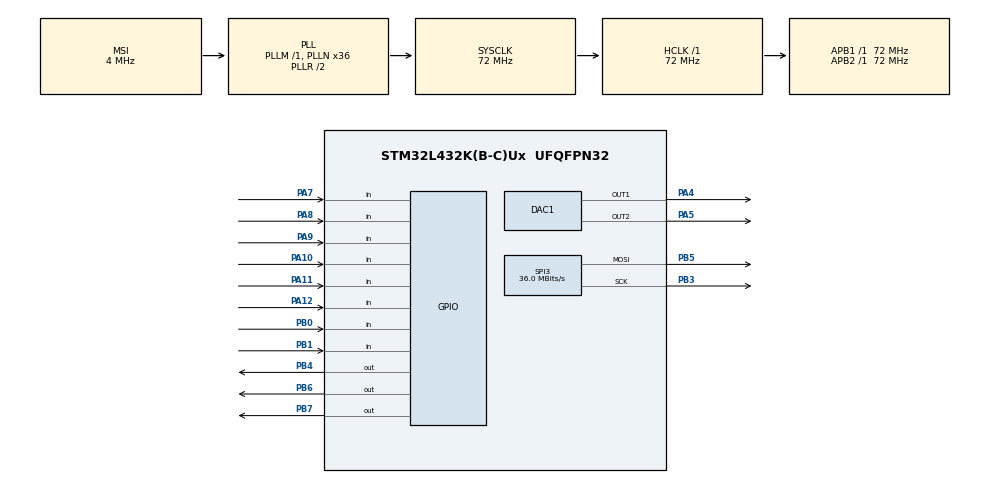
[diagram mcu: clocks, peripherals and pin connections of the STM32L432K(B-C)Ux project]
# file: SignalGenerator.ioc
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DAC1.DAC_Channel-DAC_OUT2=DAC_CHANNEL_2
DAC1.DAC_Trigger-DAC_OUT1=DAC_TRIGGER_T2_TRGO
DAC1.DAC_Trigger-DAC_OUT2=DAC_TRIGGER_T6_TRGO
Dma.DAC_CH1.0.Direction=DMA_MEMORY_TO_PERIPH
Dma.DAC_CH1.0.Instance=DMA1_Channel3
Dma.DAC_CH1.0.MemDataAlignment=DMA_MDATAALIGN_WORD
Dma.DAC_CH1.0.MemInc=DMA_MINC_ENABLE
Dma.DAC_CH1.0.Mode=DMA_CIRCULAR
Dma.DAC_CH1.0.PeriphDataAlignment=DMA_PDATAALIGN_WORD
Dma.DAC_CH1.0.PeriphInc=DMA_PINC_DISABLE
Dma.DAC_CH1.0.Priority=DMA_PRIORITY_HIGH
Dma.DAC_CH2.1.Direction=DMA_MEMORY_TO_PERIPH
Dma.DAC_CH2.1.Instance=DMA1_Channel4
Dma.DAC_CH2.1.MemDataAlignment=DMA_MDATAALIGN_WORD
Dma.DAC_CH2.1.MemInc=DMA_MINC_ENABLE
Dma.DAC_CH2.1.Mode=DMA_CIRCULAR
Dma.DAC_CH2.1.PeriphDataAlignment=DMA_PDATAALIGN_WORD
Dma.DAC_CH2.1.PeriphInc=DMA_PINC_DISABLE
Dma.DAC_CH2.1.Priority=DMA_PRIORITY_HIGH
Dma.Request0=DAC_CH1
Dma.Request1=DAC_CH2
Mcu.Family=STM32L4
Mcu.Name=STM32L432K(B-C)Ux
Mcu.Package=UFQFPN32
NVIC.DMA1_Channel3_IRQn=true\:0\:0\:false\:false\:true\:false\:true\:true
NVIC.DMA1_Channel4_IRQn=true\:0\:0\:false\:false\:true\:false\:true\:true
NVIC.PriorityGroup=NVIC_PRIORITYGROUP_4
NVIC.TIM1_UP_TIM16_IRQn=true\:0\:0\:false\:false\:true\:true\:true\:true
NVIC.TIM7_IRQn=true\:0\:0\:false\:false\:true\:true\:true\:true
PA0.GPIO_Label=MCO [High speed clock in]
PA0.Mode=HSE-External-Clock-Source-for-LittleOrca
PA0.Signal=RCC_CK_IN
PA10.GPIO_PuPd=GPIO_PULLUP
PA10.Signal=GPIO_Input
PA11.GPIO_PuPd=GPIO_PULLUP
PA11.Signal=GPIO_Input
PA12.GPIO_PuPd=GPIO_PULLUP
PA12.Signal=GPIO_Input
PA13\ (JTMS-SWDIO).GPIO_Label=SWDIO
PA13\ (JTMS-SWDIO).Mode=Serial_Wire
PA13\ (JTMS-SWDIO).Signal=SYS_JTMS-SWDIO
PA14\ (JTCK-SWCLK).GPIO_Label=SWCLK
PA14\ (JTCK-SWCLK).Mode=Serial_Wire
PA14\ (JTCK-SWCLK).Signal=SYS_JTCK-SWCLK
PA15\ (JTDI).GPIO_Label=VCP_RX
PA15\ (JTDI).Signal=USART2_RX
PA2.GPIO_Label=VCP_TX
PA2.Signal=USART2_TX
PA4.Signal=COMP_DAC11_group
PA5.Signal=COMP_DAC12_group
PA7.GPIO_PuPd=GPIO_PULLUP
PA7.Signal=GPIO_Input
PA8.GPIO_PuPd=GPIO_PULLUP
PA8.Signal=GPIO_Input
PA9.GPIO_PuPd=GPIO_PULLUP
PA9.Signal=GPIO_Input
PB0.GPIO_PuPd=GPIO_PULLUP
PB0.Signal=GPIO_Input
PB1.GPIO_PuPd=GPIO_PULLUP
PB1.Signal=GPIO_Input
PB3\ (JTDO-TRACESWO).Mode=TX_Only_Simplex_Unidirect_Master
PB3\ (JTDO-TRACESWO).Signal=SPI3_SCK
PB4\ (NJTRST).Signal=GPIO_Output
PB5.Mode=TX_Only_Simplex_Unidirect_Master
PB5.Signal=SPI3_MOSI
PB6.Signal=GPIO_Output
PB7.Signal=GPIO_Output
PC14-OSC32_IN\ (PC14).Mode=LSE-External-Oscillator
PC14-OSC32_IN\ (PC14).Signal=RCC_OSC32_IN
PC15-OSC32_OUT\ (PC15).Mode=LSE-External-Oscillator
PC15-OSC32_OUT\ (PC15).Signal=RCC_OSC32_OUT
ProjectManager.HeapSize=0x200
ProjectManager.StackSize=0x400
ProjectManager.TargetToolchain=STM32CubeIDE
RCC.AHBFreq_Value=72000000
RCC.APB1Freq_Value=72000000
RCC.APB1TimFreq_Value=72000000
RCC.APB2Freq_Value=72000000
RCC.APB2TimFreq_Value=72000000
RCC.CortexFreq_Value=72000000
RCC.HCLKFreq_Value=72000000
RCC.HSE_VALUE=8000000
RCC.HSI16_VALUE=16000000
RCC.HSI48_VALUE=48000000
RCC.HSI_VALUE=16000000
RCC.MSI_VALUE=4000000
RCC.PLLMUL=RCC_PLLMUL_4
RCC.PLLN=36
RCC.SYSCLKFreq_VALUE=72000000
RCC.SYSCLKSource=RCC_SYSCLKSOURCE_PLLCLK
RCC.VCOOutputFreq_Value=144000000
SH.COMP_DAC11_group.0=DAC1_OUT1,DAC_OUT1
SH.COMP_DAC12_group.0=DAC1_OUT2,DAC_OUT2
SPI3.BaudRatePrescaler=SPI_BAUDRATEPRESCALER_2
SPI3.CalculateBaudRate=36.0 MBits/s
SPI3.DataSize=SPI_DATASIZE_8BIT
SPI3.Direction=SPI_DIRECTION_2LINES
SPI3.Mode=SPI_MODE_MASTER
SPI3.VirtualType=VM_MASTER
TIM16.Period=61000
TIM16.Prescaler=1200
TIM2.AutoReloadPreload=TIM_AUTORELOAD_PRELOAD_DISABLE
TIM2.Period=624
TIM2.Prescaler=4
TIM2.TIM_MasterOutputTrigger=TIM_TRGO_UPDATE
TIM6.AutoReloadPreload=TIM_AUTORELOAD_PRELOAD_DISABLE
TIM6.Period=624
TIM6.Prescaler=4
TIM6.TIM_MasterOutputTrigger=TIM_TRGO_UPDATE
TIM7.Period=5000
TIM7.Prescaler=28
VP_TIM16_VS_ClockSourceINT.Mode=Enable_Timer
VP_TIM2_VS_ClockSourceINT.Mode=Internal
VP_TIM6_VS_ClockSourceINT.Mode=Enable_Timer
VP_TIM7_VS_ClockSourceINT.Mode=Enable_Timer
board=NUCLEO-L432KC

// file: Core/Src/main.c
/* USER CODE BEGIN Header */
/**
  ******************************************************************************
  * @file           : main.c
  * @brief          : Main program body
  ******************************************************************************
  * @attention
  *
  * Copyright (c) 2024 STMicroelectronics.
  * All rights reserved.
  *
  * This software is licensed under terms that can be found in the LICENSE file
  * in the root directory of this software component.
  * If no LICENSE file comes with this software, it is provided AS-IS.
  *
  ******************************************************************************
  */
/* USER CODE END Header */
#include "main.h"

DAC_HandleTypeDef hdac1;
DMA_HandleTypeDef hdma_dac_ch1;
DMA_HandleTypeDef hdma_dac_ch2;

SPI_HandleTypeDef hspi3;

TIM_HandleTypeDef htim2;
TIM_HandleTypeDef htim6;
TIM_HandleTypeDef htim7;
TIM_HandleTypeDef htim16;

void SystemClock_Config(void);
static void MX_GPIO_Init(void);
static void MX_DMA_Init(void);
static void MX_DAC1_Init(void);
static void MX_TIM2_Init(void);
static void MX_TIM6_Init(void);
static void MX_SPI3_Init(void);
static void MX_TIM7_Init(void);
static void MX_TIM16_Init(void);
/* USER CODE BEGIN PFP */
void cpp_main(void);
/* USER CODE END PFP */

int main(void)
{

  /* MCU Configuration--------------------------------------------------------*/

  /* Reset of all peripherals, Initializes the Flash interface and the Systick. */
  HAL_Init();

  /* Configure the system clock */
  SystemClock_Config();

  /* Initialize all configured peripherals */
  MX_GPIO_Init();
  MX_DMA_Init();
  MX_DAC1_Init();
  MX_TIM2_Init();
  MX_TIM6_Init();
  MX_SPI3_Init();
  MX_TIM7_Init();
  MX_TIM16_Init();
  /* USER CODE BEGIN 2 */
  //TIM7->DIER|=TIM_DIER_UIE_Msk;
  /* USER CODE END 2 */

  /* Infinite loop */
  /* USER CODE BEGIN WHILE */
  HAL_TIM_Base_Start_IT(&htim7);
  HAL_TIM_Base_Start_IT(&htim16);
  cpp_main();

  while (1)
  {
    /* USER CODE END WHILE */

  }
}

void SystemClock_Config(void)
{
  RCC_OscInitTypeDef RCC_OscInitStruct = {0};
  RCC_ClkInitTypeDef RCC_ClkInitStruct = {0};

  /** Configure the main internal regulator output voltage
  */
  if (HAL_PWREx_ControlVoltageScaling(PWR_REGULATOR_VOLTAGE_SCALE1) != HAL_OK)
  {
    Error_Handler();
  }

  /** Configure LSE Drive Capability
  */
  HAL_PWR_EnableBkUpAccess();
  __HAL_RCC_LSEDRIVE_CONFIG(RCC_LSEDRIVE_LOW);

  /** Initializes the RCC Oscillators according to the specified parameters
  * in the RCC_OscInitTypeDef structure.
  */
  RCC_OscInitStruct.OscillatorType = RCC_OSCILLATORTYPE_LSE|RCC_OSCILLATORTYPE_MSI;
  RCC_OscInitStruct.LSEState = RCC_LSE_ON;
  RCC_OscInitStruct.MSIState = RCC_MSI_ON;
  RCC_OscInitStruct.MSICalibrationValue = 0;
  RCC_OscInitStruct.MSIClockRange = RCC_MSIRANGE_6;
  RCC_OscInitStruct.PLL.PLLState = RCC_PLL_ON;
  RCC_OscInitStruct.PLL.PLLSource = RCC_PLLSOURCE_MSI;
  RCC_OscInitStruct.PLL.PLLM = 1;
  RCC_OscInitStruct.PLL.PLLN = 36;
  RCC_OscInitStruct.PLL.PLLP = RCC_PLLP_DIV7;
  RCC_OscInitStruct.PLL.PLLQ = RCC_PLLQ_DIV2;
  RCC_OscInitStruct.PLL.PLLR = RCC_PLLR_DIV2;
  if (HAL_RCC_OscConfig(&RCC_OscInitStruct) != HAL_OK)
  {
    Error_Handler();
  }

  /** Initializes the CPU, AHB and APB buses clocks
  */
  RCC_ClkInitStruct.ClockType = RCC_CLOCKTYPE_HCLK|RCC_CLOCKTYPE_SYSCLK
                              |RCC_CLOCKTYPE_PCLK1|RCC_CLOCKTYPE_PCLK2;
  RCC_ClkInitStruct.SYSCLKSource = RCC_SYSCLKSOURCE_PLLCLK;
  RCC_ClkInitStruct.AHBCLKDivider = RCC_SYSCLK_DIV1;
  RCC_ClkInitStruct.APB1CLKDivider = RCC_HCLK_DIV1;
  RCC_ClkInitStruct.APB2CLKDivider = RCC_HCLK_DIV1;

  if (HAL_RCC_ClockConfig(&RCC_ClkInitStruct, FLASH_LATENCY_4) != HAL_OK)
  {
    Error_Handler();
  }

  /** Enable MSI Auto calibration
  */
  HAL_RCCEx_EnableMSIPLLMode();
}

static void MX_DAC1_Init(void)
{

  DAC_ChannelConfTypeDef sConfig = {0};

  /** DAC Initialization
  */
  hdac1.Instance = DAC1;
  if (HAL_DAC_Init(&hdac1) != HAL_OK)
  {
    Error_Handler();
  }

  /** DAC channel OUT1 config
  */
  sConfig.DAC_SampleAndHold = DAC_SAMPLEANDHOLD_DISABLE;
  sConfig.DAC_Trigger = DAC_TRIGGER_T2_TRGO;
  sConfig.DAC_OutputBuffer = DAC_OUTPUTBUFFER_ENABLE;
  sConfig.DAC_ConnectOnChipPeripheral = DAC_CHIPCONNECT_DISABLE;
  sConfig.DAC_UserTrimming = DAC_TRIMMING_FACTORY;
  if (HAL_DAC_ConfigChannel(&hdac1, &sConfig, DAC_CHANNEL_1) != HAL_OK)
  {
    Error_Handler();
  }

  /** DAC channel OUT2 config
  */
  sConfig.DAC_Trigger = DAC_TRIGGER_T6_TRGO;
  if (HAL_DAC_ConfigChannel(&hdac1, &sConfig, DAC_CHANNEL_2) != HAL_OK)
  {
    Error_Handler();
  }

}

static void MX_SPI3_Init(void)
{

  /* SPI3 parameter configuration*/
  hspi3.Instance = SPI3;
  hspi3.Init.Mode = SPI_MODE_MASTER;
  hspi3.Init.Direction = SPI_DIRECTION_2LINES;
  hspi3.Init.DataSize = SPI_DATASIZE_8BIT;
  hspi3.Init.CLKPolarity = SPI_POLARITY_LOW;
  hspi3.Init.CLKPhase = SPI_PHASE_1EDGE;
  hspi3.Init.NSS = SPI_NSS_SOFT;
  hspi3.Init.BaudRatePrescaler = SPI_BAUDRATEPRESCALER_2;
  hspi3.Init.FirstBit = SPI_FIRSTBIT_MSB;
  hspi3.Init.TIMode = SPI_TIMODE_DISABLE;
  hspi3.Init.CRCCalculation = SPI_CRCCALCULATION_DISABLE;
  hspi3.Init.CRCPolynomial = 7;
  hspi3.Init.CRCLength = SPI_CRC_LENGTH_DATASIZE;
  hspi3.Init.NSSPMode = SPI_NSS_PULSE_ENABLE;
  if (HAL_SPI_Init(&hspi3) != HAL_OK)
  {
    Error_Handler();
  }

}

static void MX_TIM2_Init(void)
{

  TIM_ClockConfigTypeDef sClockSourceConfig = {0};
  TIM_MasterConfigTypeDef sMasterConfig = {0};

  htim2.Instance = TIM2;
  htim2.Init.Prescaler = 4;
  htim2.Init.CounterMode = TIM_COUNTERMODE_UP;
  htim2.Init.Period = 624;
  htim2.Init.ClockDivision = TIM_CLOCKDIVISION_DIV1;
  htim2.Init.AutoReloadPreload = TIM_AUTORELOAD_PRELOAD_DISABLE;
  if (HAL_TIM_Base_Init(&htim2) != HAL_OK)
  {
    Error_Handler();
  }
  sClockSourceConfig.ClockSource = TIM_CLOCKSOURCE_INTERNAL;
  if (HAL_TIM_ConfigClockSource(&htim2, &sClockSourceConfig) != HAL_OK)
  {
    Error_Handler();
  }
  sMasterConfig.MasterOutputTrigger = TIM_TRGO_UPDATE;
  sMasterConfig.MasterSlaveMode = TIM_MASTERSLAVEMODE_DISABLE;
  if (HAL_TIMEx_MasterConfigSynchronization(&htim2, &sMasterConfig) != HAL_OK)
  {
    Error_Handler();
  }

}

static void MX_TIM6_Init(void)
{

  TIM_MasterConfigTypeDef sMasterConfig = {0};

  htim6.Instance = TIM6;
  htim6.Init.Prescaler = 4;
  htim6.Init.CounterMode = TIM_COUNTERMODE_UP;
  htim6.Init.Period = 624;
  htim6.Init.AutoReloadPreload = TIM_AUTORELOAD_PRELOAD_DISABLE;
  if (HAL_TIM_Base_Init(&htim6) != HAL_OK)
  {
    Error_Handler();
  }
  sMasterConfig.MasterOutputTrigger = TIM_TRGO_UPDATE;
  sMasterConfig.MasterSlaveMode = TIM_MASTERSLAVEMODE_DISABLE;
  if (HAL_TIMEx_MasterConfigSynchronization(&htim6, &sMasterConfig) != HAL_OK)
  {
    Error_Handler();
  }

}

static void MX_TIM7_Init(void)
{

  TIM_MasterConfigTypeDef sMasterConfig = {0};

  htim7.Instance = TIM7;
  htim7.Init.Prescaler = 28;
  htim7.Init.CounterMode = TIM_COUNTERMODE_UP;
  htim7.Init.Period = 5000;
  htim7.Init.AutoReloadPreload = TIM_AUTORELOAD_PRELOAD_DISABLE;
  if (HAL_TIM_Base_Init(&htim7) != HAL_OK)
  {
    Error_Handler();
  }
  sMasterConfig.MasterOutputTrigger = TIM_TRGO_RESET;
  sMasterConfig.MasterSlaveMode = TIM_MASTERSLAVEMODE_DISABLE;
  if (HAL_TIMEx_MasterConfigSynchronization(&htim7, &sMasterConfig) != HAL_OK)
  {
    Error_Handler();
  }

}

static void MX_TIM16_Init(void)
{

  htim16.Instance = TIM16;
  htim16.Init.Prescaler = 1200;
  htim16.Init.CounterMode = TIM_COUNTERMODE_UP;
  htim16.Init.Period = 61000;
  htim16.Init.ClockDivision = TIM_CLOCKDIVISION_DIV1;
  htim16.Init.RepetitionCounter = 0;
  htim16.Init.AutoReloadPreload = TIM_AUTORELOAD_PRELOAD_DISABLE;
  if (HAL_TIM_Base_Init(&htim16) != HAL_OK)
  {
    Error_Handler();
  }

}

static void MX_DMA_Init(void)
{

  /* DMA controller clock enable */
  __HAL_RCC_DMA1_CLK_ENABLE();

  /* DMA interrupt init */
  /* DMA1_Channel3_IRQn interrupt configuration */
  HAL_NVIC_SetPriority(DMA1_Channel3_IRQn, 0, 0);
  HAL_NVIC_EnableIRQ(DMA1_Channel3_IRQn);
  /* DMA1_Channel4_IRQn interrupt configuration */
  HAL_NVIC_SetPriority(DMA1_Channel4_IRQn, 0, 0);
  HAL_NVIC_EnableIRQ(DMA1_Channel4_IRQn);

}

static void MX_GPIO_Init(void)
{
  GPIO_InitTypeDef GPIO_InitStruct = {0};

  /* GPIO Ports Clock Enable */
  __HAL_RCC_GPIOC_CLK_ENABLE();
  __HAL_RCC_GPIOA_CLK_ENABLE();
  __HAL_RCC_GPIOB_CLK_ENABLE();

  /*Configure GPIO pin Output Level */
  HAL_GPIO_WritePin(GPIOB, GPIO_PIN_4|GPIO_PIN_6|GPIO_PIN_7, GPIO_PIN_RESET);

  /*Configure GPIO pin : VCP_TX_Pin */
  GPIO_InitStruct.Pin = VCP_TX_Pin;
  GPIO_InitStruct.Mode = GPIO_MODE_AF_PP;
  GPIO_InitStruct.Pull = GPIO_NOPULL;
  GPIO_InitStruct.Speed = GPIO_SPEED_FREQ_VERY_HIGH;
  GPIO_InitStruct.Alternate = GPIO_AF7_USART2;
  HAL_GPIO_Init(VCP_TX_GPIO_Port, &GPIO_InitStruct);

  /*Configure GPIO pins : PA7 PA8 PA9 PA10
                           PA11 PA12 */
  GPIO_InitStruct.Pin = GPIO_PIN_7|GPIO_PIN_8|GPIO_PIN_9|GPIO_PIN_10
                          |GPIO_PIN_11|GPIO_PIN_12;
  GPIO_InitStruct.Mode = GPIO_MODE_INPUT;
  GPIO_InitStruct.Pull = GPIO_PULLUP;
  HAL_GPIO_Init(GPIOA, &GPIO_InitStruct);

  /*Configure GPIO pins : PB0 PB1 */
  GPIO_InitStruct.Pin = GPIO_PIN_0|GPIO_PIN_1;
  GPIO_InitStruct.Mode = GPIO_MODE_INPUT;
  GPIO_InitStruct.Pull = GPIO_PULLUP;
  HAL_GPIO_Init(GPIOB, &GPIO_InitStruct);

  /*Configure GPIO pin : VCP_RX_Pin */
  GPIO_InitStruct.Pin = VCP_RX_Pin;
  GPIO_InitStruct.Mode = GPIO_MODE_AF_PP;
  GPIO_InitStruct.Pull = GPIO_NOPULL;
  GPIO_InitStruct.Speed = GPIO_SPEED_FREQ_VERY_HIGH;
  GPIO_InitStruct.Alternate = GPIO_AF3_USART2;
  HAL_GPIO_Init(VCP_RX_GPIO_Port, &GPIO_InitStruct);

  /*Configure GPIO pins : PB4 PB6 PB7 */
  GPIO_InitStruct.Pin = GPIO_PIN_4|GPIO_PIN_6|GPIO_PIN_7;
  GPIO_InitStruct.Mode = GPIO_MODE_OUTPUT_PP;
  GPIO_InitStruct.Pull = GPIO_NOPULL;
  GPIO_InitStruct.Speed = GPIO_SPEED_FREQ_LOW;
  HAL_GPIO_Init(GPIOB, &GPIO_InitStruct);

}

void Error_Handler(void)
{
  __disable_irq();
  while (1)
  {
  }
}
